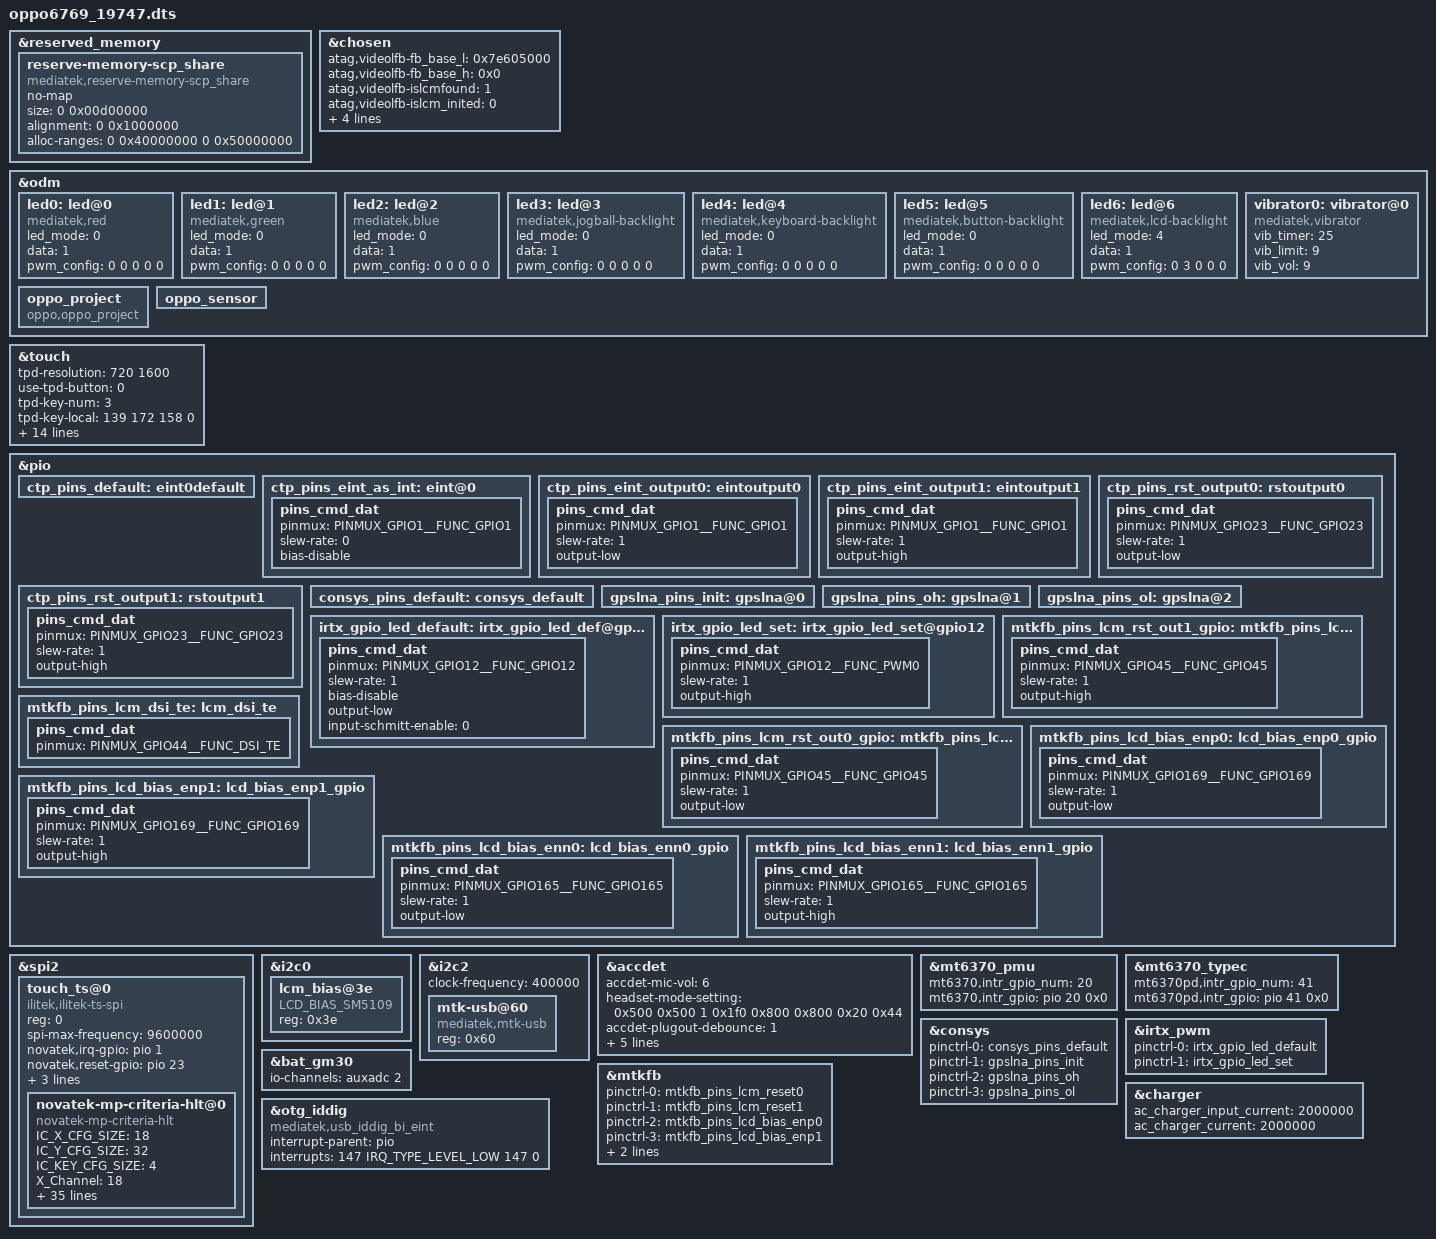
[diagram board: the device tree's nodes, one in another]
/*
 * Copyright (C) 2019 MediaTek Inc.
 *
 * This program is free software; you can redistribute it and/or modify
 * it under the terms of the GNU General Public License version 2 as
 * published by the Free Software Foundation.
 *
 * This program is distributed in the hope that it will be useful,
 * but WITHOUT ANY WARRANTY; without even the implied warranty of
 * MERCHANTABILITY or FITNESS FOR A PARTICULAR PURPOSE.
 * See http://www.gnu.org/licenses/gpl-2.0.html for more details.
 */

/dts-v1/;
/plugin/;
#include <dt-bindings/interrupt-controller/irq.h>
#include <dt-bindings/interrupt-controller/arm-gic.h>
#include <dt-bindings/pinctrl/mt6768-pinfunc.h>

&reserved_memory {
	reserve-memory-scp_share {
		compatible = "mediatek,reserve-memory-scp_share";
		no-map;
		size = <0 0x00d00000>;
		alignment = <0 0x1000000>;
		alloc-ranges = <0 0x40000000 0 0x50000000>;
	};
};

/* chosen */
&chosen {

	atag,videolfb-fb_base_l = <0x7e605000>;
	atag,videolfb-fb_base_h = <0x0>;
	atag,videolfb-islcmfound = <1>;
	atag,videolfb-islcm_inited = <0>;
	atag,videolfb-fps= <6000>;
	atag,videolfb-vramSize= <0x017e8000>;
	atag,videolfb-lcmname=
		"hx83112b_fhdp_dsi_cmd_auo_rt5081_drv";
};

&odm {
	led0:led@0 {
		compatible = "mediatek,red";
		led_mode = <0>;
		data = <1>;
		pwm_config = <0 0 0 0 0>;
	};
	led1:led@1 {
		compatible = "mediatek,green";
		led_mode = <0>;
		data = <1>;
		pwm_config = <0 0 0 0 0>;
	};
	led2:led@2 {
		compatible = "mediatek,blue";
		led_mode = <0>;
		data = <1>;
		pwm_config = <0 0 0 0 0>;
	};
	led3:led@3 {
		compatible = "mediatek,jogball-backlight";
		led_mode = <0>;
		data = <1>;
		pwm_config = <0 0 0 0 0>;
	};
	led4:led@4 {
		compatible = "mediatek,keyboard-backlight";
		led_mode = <0>;
		data = <1>;
		pwm_config = <0 0 0 0 0>;
	};
	led5:led@5 {
		compatible = "mediatek,button-backlight";
		led_mode = <0>;
		data = <1>;
		pwm_config = <0 0 0 0 0>;
	};
	led6:led@6 {
		compatible = "mediatek,lcd-backlight";
		led_mode = <4>;
		data = <1>;
		pwm_config = <0 3 0 0 0>;
	};
	vibrator0:vibrator@0 {
		compatible = "mediatek,vibrator";
		vib_timer = <25>;
		vib_limit = <9>;
		vib_vol= <9>;
	};
	
//#ifdef VENDOR_EDIT
/*Bin.Li@EXP.BSP.bootloader.bootflow, 2017/05/15, Add for oppo project */
	oppo_project:oppo_project {
		compatible = "oppo,oppo_project";
	};
//#endif /*VENDOR_EDIT*/
//#ifdef VENDOR_EDIT
/*Fei.Mo@PSW.BSP.Sensor, 2017/12/18, Add for sensor calibration paramaters */
       oppo_sensor:oppo_sensor {
       };
//#endif /*VENDOR_EDIT*
};

/* TOUCH start */
&touch {
	tpd-resolution = <720 1600>;
	use-tpd-button = <0>;
	tpd-key-num = <3>;
	tpd-key-local= <139 172 158 0>;
	tpd-key-dim-local = <90 883 100 40 230
				883 100 40 370 883 100 40 0 0 0 0>;
	tpd-max-touch-num = <10>;
	tpd-filter-enable = <0>;
	tpd-filter-pixel-density = <168>;
	tpd-filter-custom-prameters = <0 0 0 0 0 0 0 0 0 0 0 0>;
	tpd-filter-custom-speed = <0 0 0>;
	pinctrl-names = "default", "state_eint_as_int",
		"state_eint_output0", "state_eint_output1",
		"state_rst_output0", "state_rst_output1";
	pinctrl-0 = <&ctp_pins_default>;
	pinctrl-1 = <&ctp_pins_eint_as_int>;
	pinctrl-2 = <&ctp_pins_eint_output0>;
	pinctrl-3 = <&ctp_pins_eint_output1>;
	pinctrl-4 = <&ctp_pins_rst_output0>;
	pinctrl-5 = <&ctp_pins_rst_output1>;
	status = "okay";
};
&pio {
	ctp_pins_default: eint0default {
	};
	ctp_pins_eint_as_int: eint@0 {
		pins_cmd_dat {
			pinmux = <PINMUX_GPIO1__FUNC_GPIO1>;
			slew-rate = <0>;
			bias-disable;
		};
	};
	ctp_pins_eint_output0: eintoutput0 {
		pins_cmd_dat {
			pinmux = <PINMUX_GPIO1__FUNC_GPIO1>;
			slew-rate = <1>;
			output-low;
		};
	};
	ctp_pins_eint_output1: eintoutput1 {
		pins_cmd_dat {
			pinmux = <PINMUX_GPIO1__FUNC_GPIO1>;
			slew-rate = <1>;
			output-high;
	};
	};
	ctp_pins_rst_output0: rstoutput0 {
		pins_cmd_dat {
			pinmux = <PINMUX_GPIO23__FUNC_GPIO23>;
			slew-rate = <1>;
			output-low;
		};
	};
	ctp_pins_rst_output1: rstoutput1 {
		pins_cmd_dat {
			pinmux = <PINMUX_GPIO23__FUNC_GPIO23>;
			slew-rate = <1>;
			output-high;
		};
	};
};
//#ifdef ODM_WT_EDIT
//#Tongxing.Liu@ODM_WT.BSP.Touchscreen.Base,2019/10/04,bringup add for xl and hlt touchscreen mould dts config.
&spi2 {
    #address-cells = <1>;
    #size-cells = <0>;
    touch_ts@0 {
        reg = <0>;
        compatible = "ilitek,ilitek-ts-spi","novatek,NVT-ts-spi";
	status = "okay";
	/* touch spi config */
        spi-max-frequency = <9600000>;
	/* novatek touch gpio config */
	novatek,irq-gpio = <&pio 1 0>;
	novatek,reset-gpio = <&pio 23 0>;
	novatek,reset_global_gpio = <&pio 45 0>;
	/* 672A, 525B */
	novatek,swrst-n8-addr = <0x03F0FE>;
	/* MP config  */
	novatek,mp-support-dt;
	novatek-mp-criteria-hlt@0 {
		#address-cells = <1>;
		#size-cells = <0>;
		compatible = "novatek-mp-criteria-hlt";
	        /* MP Config */
		IC_X_CFG_SIZE = <18>;
		IC_Y_CFG_SIZE = <32>;
		IC_KEY_CFG_SIZE = <4>;
		X_Channel = <18>;
		Y_Channel = <32>;
		AIN_X = <0 1 2 3 4 5 6 7 8 9 10 11 12 13 14 15 16 17>;
		AIN_Y = <0 1 2 3 4 5 6 7 8 9 10 11 12 13 14 15 16 17 18 19
							20 21 22 23 24 25 26 27 28 29 30 31>;
		AIN_KEY = <0 1 2 0xFF>;

		/* MP Criteria */
		PS_Config_Lmt_Short_Rawdata_P = <
			14008 14008 14008 14008 14008 14008 14008 14008 14008 14008 14008 14008 14008 14008 14008 14008 14008 14008
			14008 14008 14008 14008 14008 14008 14008 14008 14008 14008 14008 14008 14008 14008 14008 14008 14008 14008
			14008 14008 14008 14008 14008 14008 14008 14008 14008 14008 14008 14008 14008 14008 14008 14008 14008 14008
			14008 14008 14008 14008 14008 14008 14008 14008 14008 14008 14008 14008 14008 14008 14008 14008 14008 14008
			14008 14008 14008 14008 14008 14008 14008 14008 14008 14008 14008 14008 14008 14008 14008 14008 14008 14008
			14008 14008 14008 14008 14008 14008 14008 14008 14008 14008 14008 14008 14008 14008 14008 14008 14008 14008
			14008 14008 14008 14008 14008 14008 14008 14008 14008 14008 14008 14008 14008 14008 14008 14008 14008 14008
			14008 14008 14008 14008 14008 14008 14008 14008 14008 14008 14008 14008 14008 14008 14008 14008 14008 14008
			14008 14008 14008 14008 14008 14008 14008 14008 14008 14008 14008 14008 14008 14008 14008 14008 14008 14008
			14008 14008 14008 14008 14008 14008 14008 14008 14008 14008 14008 14008 14008 14008 14008 14008 14008 14008
			14008 14008 14008 14008 14008 14008 14008 14008 14008 14008 14008 14008 14008 14008 14008 14008 14008 14008
			14008 14008 14008 14008 14008 14008 14008 14008 14008 14008 14008 14008 14008 14008 14008 14008 14008 14008
			14008 14008 14008 14008 14008 14008 14008 14008 14008 14008 14008 14008 14008 14008 14008 14008 14008 14008
			14008 14008 14008 14008 14008 14008 14008 14008 14008 14008 14008 14008 14008 14008 14008 14008 14008 14008
			14008 14008 14008 14008 14008 14008 14008 14008 14008 14008 14008 14008 14008 14008 14008 14008 14008 14008
			14008 14008 14008 14008 14008 14008 14008 14008 14008 14008 14008 14008 14008 14008 14008 14008 14008 14008
			14008 14008 14008 14008 14008 14008 14008 14008 14008 14008 14008 14008 14008 14008 14008 14008 14008 14008
			14008 14008 14008 14008 14008 14008 14008 14008 14008 14008 14008 14008 14008 14008 14008 14008 14008 14008
			14008 14008 14008 14008 14008 14008 14008 14008 14008 14008 14008 14008 14008 14008 14008 14008 14008 14008
			14008 14008 14008 14008 14008 14008 14008 14008 14008 14008 14008 14008 14008 14008 14008 14008 14008 14008
			14008 14008 14008 14008 14008 14008 14008 14008 14008 14008 14008 14008 14008 14008 14008 14008 14008 14008
			14008 14008 14008 14008 14008 14008 14008 14008 14008 14008 14008 14008 14008 14008 14008 14008 14008 14008
			14008 14008 14008 14008 14008 14008 14008 14008 14008 14008 14008 14008 14008 14008 14008 14008 14008 14008
			14008 14008 14008 14008 14008 14008 14008 14008 14008 14008 14008 14008 14008 14008 14008 14008 14008 14008
			14008 14008 14008 14008 14008 14008 14008 14008 14008 14008 14008 14008 14008 14008 14008 14008 14008 14008
			14008 14008 14008 14008 14008 14008 14008 14008 14008 14008 14008 14008 14008 14008 14008 14008 14008 14008
			14008 14008 14008 14008 14008 14008 14008 14008 14008 14008 14008 14008 14008 14008 14008 14008 14008 14008
			14008 14008 14008 14008 14008 14008 14008 14008 14008 14008 14008 14008 14008 14008 14008 14008 14008 14008
			14008 14008 14008 14008 14008 14008 14008 14008 14008 14008 14008 14008 14008 14008 14008 14008 14008 14008
			14008 14008 14008 14008 14008 14008 14008 14008 14008 14008 14008 14008 14008 14008 14008 14008 14008 14008
			14008 14008 14008 14008 14008 14008 14008 14008 14008 14008 14008 14008 14008 14008 14008 14008 14008 14008
			14008 14008 14008 14008 14008 14008 14008 14008 14008 14008 14008 14008 14008 14008 14008 14008 14008 14008
			>;

		PS_Config_Lmt_Short_Rawdata_N = <
			10000 10000 10000 10000 10000 10000 10000 10000 10000 10000 10000 10000 10000 10000 10000 10000 10000 10000
			10000 10000 10000 10000 10000 10000 10000 10000 10000 10000 10000 10000 10000 10000 10000 10000 10000 10000
			10000 10000 10000 10000 10000 10000 10000 10000 10000 10000 10000 10000 10000 10000 10000 10000 10000 10000
			10000 10000 10000 10000 10000 10000 10000 10000 10000 10000 10000 10000 10000 10000 10000 10000 10000 10000
			10000 10000 10000 10000 10000 10000 10000 10000 10000 10000 10000 10000 10000 10000 10000 10000 10000 10000
			10000 10000 10000 10000 10000 10000 10000 10000 10000 10000 10000 10000 10000 10000 10000 10000 10000 10000
			10000 10000 10000 10000 10000 10000 10000 10000 10000 10000 10000 10000 10000 10000 10000 10000 10000 10000
			10000 10000 10000 10000 10000 10000 10000 10000 10000 10000 10000 10000 10000 10000 10000 10000 10000 10000
			10000 10000 10000 10000 10000 10000 10000 10000 10000 10000 10000 10000 10000 10000 10000 10000 10000 10000
			10000 10000 10000 10000 10000 10000 10000 10000 10000 10000 10000 10000 10000 10000 10000 10000 10000 10000
			10000 10000 10000 10000 10000 10000 10000 10000 10000 10000 10000 10000 10000 10000 10000 10000 10000 10000
			10000 10000 10000 10000 10000 10000 10000 10000 10000 10000 10000 10000 10000 10000 10000 10000 10000 10000
			10000 10000 10000 10000 10000 10000 10000 10000 10000 10000 10000 10000 10000 10000 10000 10000 10000 10000
			10000 10000 10000 10000 10000 10000 10000 10000 10000 10000 10000 10000 10000 10000 10000 10000 10000 10000
			10000 10000 10000 10000 10000 10000 10000 10000 10000 10000 10000 10000 10000 10000 10000 10000 10000 10000
			10000 10000 10000 10000 10000 10000 10000 10000 10000 10000 10000 10000 10000 10000 10000 10000 10000 10000
			10000 10000 10000 10000 10000 10000 10000 10000 10000 10000 10000 10000 10000 10000 10000 10000 10000 10000
			10000 10000 10000 10000 10000 10000 10000 10000 10000 10000 10000 10000 10000 10000 10000 10000 10000 10000
			10000 10000 10000 10000 10000 10000 10000 10000 10000 10000 10000 10000 10000 10000 10000 10000 10000 10000
			10000 10000 10000 10000 10000 10000 10000 10000 10000 10000 10000 10000 10000 10000 10000 10000 10000 10000
			10000 10000 10000 10000 10000 10000 10000 10000 10000 10000 10000 10000 10000 10000 10000 10000 10000 10000
			10000 10000 10000 10000 10000 10000 10000 10000 10000 10000 10000 10000 10000 10000 10000 10000 10000 10000
			10000 10000 10000 10000 10000 10000 10000 10000 10000 10000 10000 10000 10000 10000 10000 10000 10000 10000
			10000 10000 10000 10000 10000 10000 10000 10000 10000 10000 10000 10000 10000 10000 10000 10000 10000 10000
			10000 10000 10000 10000 10000 10000 10000 10000 10000 10000 10000 10000 10000 10000 10000 10000 10000 10000
			10000 10000 10000 10000 10000 10000 10000 10000 10000 10000 10000 10000 10000 10000 10000 10000 10000 10000
			10000 10000 10000 10000 10000 10000 10000 10000 10000 10000 10000 10000 10000 10000 10000 10000 10000 10000
			10000 10000 10000 10000 10000 10000 10000 10000 10000 10000 10000 10000 10000 10000 10000 10000 10000 10000
			10000 10000 10000 10000 10000 10000 10000 10000 10000 10000 10000 10000 10000 10000 10000 10000 10000 10000
			10000 10000 10000 10000 10000 10000 10000 10000 10000 10000 10000 10000 10000 10000 10000 10000 10000 10000
			10000 10000 10000 10000 10000 10000 10000 10000 10000 10000 10000 10000 10000 10000 10000 10000 10000 10000
			10000 10000 10000 10000 10000 10000 10000 10000 10000 10000 10000 10000 10000 10000 10000 10000 10000 10000
			>;

		PS_Config_Lmt_Open_Rawdata_P = <
			4096 4096 4096 4096 4096 4096 4096 4096 4096 4096 4096 4096 4096 4096 4096 4096 4096 4096
			4096 4096 4096 4096 4096 4096 4096 4096 4096 4096 4096 4096 4096 4096 4096 4096 4096 4096
			4096 4096 4096 4096 4096 4096 4096 4096 4096 4096 4096 4096 4096 4096 4096 4096 4096 4096
			4096 4096 4096 4096 4096 4096 4096 4096 4096 4096 4096 4096 4096 4096 4096 4096 4096 4096
			4096 4096 4096 4096 4096 4096 4096 4096 4096 4096 4096 4096 4096 4096 4096 4096 4096 4096
			4096 4096 4096 4096 4096 4096 4096 4096 4096 4096 4096 4096 4096 4096 4096 4096 4096 4096
			4096 4096 4096 4096 4096 4096 4096 4096 4096 4096 4096 4096 4096 4096 4096 4096 4096 4096
			4096 4096 4096 4096 4096 4096 4096 4096 4096 4096 4096 4096 4096 4096 4096 4096 4096 4096
			4096 4096 4096 4096 4096 4096 4096 4096 4096 4096 4096 4096 4096 4096 4096 4096 4096 4096
			4096 4096 4096 4096 4096 4096 4096 4096 4096 4096 4096 4096 4096 4096 4096 4096 4096 4096
			4096 4096 4096 4096 4096 4096 4096 4096 4096 4096 4096 4096 4096 4096 4096 4096 4096 4096
			4096 4096 4096 4096 4096 4096 4096 4096 4096 4096 4096 4096 4096 4096 4096 4096 4096 4096
			4096 4096 4096 4096 4096 4096 4096 4096 4096 4096 4096 4096 4096 4096 4096 4096 4096 4096
			4096 4096 4096 4096 4096 4096 4096 4096 4096 4096 4096 4096 4096 4096 4096 4096 4096 4096
			4096 4096 4096 4096 4096 4096 4096 4096 4096 4096 4096 4096 4096 4096 4096 4096 4096 4096
			4096 4096 4096 4096 4096 4096 4096 4096 4096 4096 4096 4096 4096 4096 4096 4096 4096 4096
			4096 4096 4096 4096 4096 4096 4096 4096 4096 4096 4096 4096 4096 4096 4096 4096 4096 4096
			4096 4096 4096 4096 4096 4096 4096 4096 4096 4096 4096 4096 4096 4096 4096 4096 4096 4096
			4096 4096 4096 4096 4096 4096 4096 4096 4096 4096 4096 4096 4096 4096 4096 4096 4096 4096
			4096 4096 4096 4096 4096 4096 4096 4096 4096 4096 4096 4096 4096 4096 4096 4096 4096 4096
			4096 4096 4096 4096 4096 4096 4096 4096 4096 4096 4096 4096 4096 4096 4096 4096 4096 4096
			4096 4096 4096 4096 4096 4096 4096 4096 4096 4096 4096 4096 4096 4096 4096 4096 4096 4096
			4096 4096 4096 4096 4096 4096 4096 4096 4096 4096 4096 4096 4096 4096 4096 4096 4096 4096
			4096 4096 4096 4096 4096 4096 4096 4096 4096 4096 4096 4096 4096 4096 4096 4096 4096 4096
			4096 4096 4096 4096 4096 4096 4096 4096 4096 4096 4096 4096 4096 4096 4096 4096 4096 4096
			4096 4096 4096 4096 4096 4096 4096 4096 4096 4096 4096 4096 4096 4096 4096 4096 4096 4096
			4096 4096 4096 4096 4096 4096 4096 4096 4096 4096 4096 4096 4096 4096 4096 4096 4096 4096
			4096 4096 4096 4096 4096 4096 4096 4096 4096 4096 4096 4096 4096 4096 4096 4096 4096 4096
			4096 4096 4096 4096 4096 4096 4096 4096 4096 4096 4096 4096 4096 4096 4096 4096 4096 4096
			4096 4096 4096 4096 4096 4096 4096 4096 4096 4096 4096 4096 4096 4096 4096 4096 4096 4096
			4096 4096 4096 4096 4096 4096 4096 4096 4096 4096 4096 4096 4096 4096 4096 4096 4096 4096
			4096 4096 4096 4096 4096 4096 4096 4096 4096 4096 4096 4096 4096 4096 4096 4096 4096 4096
			>;

		PS_Config_Lmt_Open_Rawdata_N = <
			50 50 50 50 50 50 50 50 50 50 50 50 50 50 50 50 50 50
			50 50 50 50 50 50 50 50 50 50 50 50 50 50 50 50 50 50
			50 50 50 50 50 50 50 50 50 50 50 50 50 50 50 50 50 50
			50 50 50 50 50 50 50 50 50 50 50 50 50 50 50 50 50 50
			50 50 50 50 50 50 50 50 50 50 50 50 50 50 50 50 50 50
			50 50 50 50 50 50 50 50 50 50 50 50 50 50 50 50 50 50
			50 50 50 50 50 50 50 50 50 50 50 50 50 50 50 50 50 50
			50 50 50 50 50 50 50 50 50 50 50 50 50 50 50 50 50 50
			50 50 50 50 50 50 50 50 50 50 50 50 50 50 50 50 50 50
			50 50 50 50 50 50 50 50 50 50 50 50 50 50 50 50 50 50
			50 50 50 50 50 50 50 50 50 50 50 50 50 50 50 50 50 50
			50 50 50 50 50 50 50 50 50 50 50 50 50 50 50 50 50 50
			50 50 50 50 50 50 50 50 50 50 50 50 50 50 50 50 50 50
			50 50 50 50 50 50 50 50 50 50 50 50 50 50 50 50 50 50
			50 50 50 50 50 50 50 50 50 50 50 50 50 50 50 50 50 50
			50 50 50 50 50 50 50 50 50 50 50 50 50 50 50 50 50 50
			50 50 50 50 50 50 50 50 50 50 50 50 50 50 50 50 50 50
			50 50 50 50 50 50 50 50 50 50 50 50 50 50 50 50 50 50
			50 50 50 50 50 50 50 50 50 50 50 50 50 50 50 50 50 50
			50 50 50 50 50 50 50 50 50 50 50 50 50 50 50 50 50 50
			50 50 50 50 50 50 50 50 50 50 50 50 50 50 50 50 50 50
			50 50 50 50 50 50 50 50 50 50 50 50 50 50 50 50 50 50
			50 50 50 50 50 50 50 50 50 50 50 50 50 50 50 50 50 50
			50 50 50 50 50 50 50 50 50 50 50 50 50 50 50 50 50 50
			50 50 50 50 50 50 50 50 50 50 50 50 50 50 50 50 50 50
			50 50 50 50 50 50 50 50 50 50 50 50 50 50 50 50 50 50
			50 50 50 50 50 50 50 50 50 50 50 50 50 50 50 50 50 50
			50 50 50 50 50 50 50 50 50 50 50 50 50 50 50 50 50 50
			50 50 50 50 50 50 50 50 50 50 50 50 50 50 50 50 50 50
			50 50 50 50 50 50 50 50 50 50 50 50 50 50 50 50 50 50
			50 50 50 50 50 50 50 50 50 50 50 50 50 50 50 50 50 50
			50 50 50 50 50 50 50 50 50 50 50 50 50 50 50 50 50 50
			>;

		PS_Config_Lmt_FW_Rawdata_P = <
			1920 1920 1920 1920 1920 1920 1920 1920 1920 1920 1920 1920 1920 1920 1920 1920 1920 1920
			1920 1920 1920 1920 1920 1920 1920 1920 1920 1920 1920 1920 1920 1920 1920 1920 1920 1920
			1920 1920 1920 1920 1920 1920 1920 1920 1920 1920 1920 1920 1920 1920 1920 1920 1920 1920
			1920 1920 1920 1920 1920 1920 1920 1920 1920 1920 1920 1920 1920 1920 1920 1920 1920 1920
			1920 1920 1920 1920 1920 1920 1920 1920 1920 1920 1920 1920 1920 1920 1920 1920 1920 1920
			1920 1920 1920 1920 1920 1920 1920 1920 1920 1920 1920 1920 1920 1920 1920 1920 1920 1920
			1920 1920 1920 1920 1920 1920 1920 1920 1920 1920 1920 1920 1920 1920 1920 1920 1920 1920
			1920 1920 1920 1920 1920 1920 1920 1920 1920 1920 1920 1920 1920 1920 1920 1920 1920 1920
			1920 1920 1920 1920 1920 1920 1920 1920 1920 1920 1920 1920 1920 1920 1920 1920 1920 1920
			1920 1920 1920 1920 1920 1920 1920 1920 1920 1920 1920 1920 1920 1920 1920 1920 1920 1920
			1920 1920 1920 1920 1920 1920 1920 1920 1920 1920 1920 1920 1920 1920 1920 1920 1920 1920
			1920 1920 1920 1920 1920 1920 1920 1920 1920 1920 1920 1920 1920 1920 1920 1920 1920 1920
			1920 1920 1920 1920 1920 1920 1920 1920 1920 1920 1920 1920 1920 1920 1920 1920 1920 1920
			1920 1920 1920 1920 1920 1920 1920 1920 1920 1920 1920 1920 1920 1920 1920 1920 1920 1920
			1920 1920 1920 1920 1920 1920 1920 1920 1920 1920 1920 1920 1920 1920 1920 1920 1920 1920
			1920 1920 1920 1920 1920 1920 1920 1920 1920 1920 1920 1920 1920 1920 1920 1920 1920 1920
			1920 1920 1920 1920 1920 1920 1920 1920 1920 1920 1920 1920 1920 1920 1920 1920 1920 1920
			1920 1920 1920 1920 1920 1920 1920 1920 1920 1920 1920 1920 1920 1920 1920 1920 1920 1920
			1920 1920 1920 1920 1920 1920 1920 1920 1920 1920 1920 1920 1920 1920 1920 1920 1920 1920
			1920 1920 1920 1920 1920 1920 1920 1920 1920 1920 1920 1920 1920 1920 1920 1920 1920 1920
			1920 1920 1920 1920 1920 1920 1920 1920 1920 1920 1920 1920 1920 1920 1920 1920 1920 1920
			1920 1920 1920 1920 1920 1920 1920 1920 1920 1920 1920 1920 1920 1920 1920 1920 1920 1920
			1920 1920 1920 1920 1920 1920 1920 1920 1920 1920 1920 1920 1920 1920 1920 1920 1920 1920
			1920 1920 1920 1920 1920 1920 1920 1920 1920 1920 1920 1920 1920 1920 1920 1920 1920 1920
			1920 1920 1920 1920 1920 1920 1920 1920 1920 1920 1920 1920 1920 1920 1920 1920 1920 1920
			1920 1920 1920 1920 1920 1920 1920 1920 1920 1920 1920 1920 1920 1920 1920 1920 1920 1920
			1920 1920 1920 1920 1920 1920 1920 1920 1920 1920 1920 1920 1920 1920 1920 1920 1920 1920
			1920 1920 1920 1920 1920 1920 1920 1920 1920 1920 1920 1920 1920 1920 1920 1920 1920 1920
			1920 1920 1920 1920 1920 1920 1920 1920 1920 1920 1920 1920 1920 1920 1920 1920 1920 1920
			1920 1920 1920 1920 1920 1920 1920 1920 1920 1920 1920 1920 1920 1920 1920 1920 1920 1920
			1920 1920 1920 1920 1920 1920 1920 1920 1920 1920 1920 1920 1920 1920 1920 1920 1920 1920
			1920 1920 1920 1920 1920 1920 1920 1920 1920 1920 1920 1920 1920 1920 1920 1920 1920 1920
			>;

		PS_Config_Lmt_FW_Rawdata_N = <
			240 240 240 240 240 240 240 240 240 240 240 240 240 240 240 240 240 240
			240 240 240 240 240 240 240 240 240 240 240 240 240 240 240 240 240 240
			240 240 240 240 240 240 240 240 240 240 240 240 240 240 240 240 240 240
			240 240 240 240 240 240 240 240 240 240 240 240 240 240 240 240 240 240
			240 240 240 240 240 240 240 240 240 240 240 240 240 240 240 240 240 240
			240 240 240 240 240 240 240 240 240 240 240 240 240 240 240 240 240 240
			240 240 240 240 240 240 240 240 240 240 240 240 240 240 240 240 240 240
			240 240 240 240 240 240 240 240 240 240 240 240 240 240 240 240 240 240
			240 240 240 240 240 240 240 240 240 240 240 240 240 240 240 240 240 240
			240 240 240 240 240 240 240 240 240 240 240 240 240 240 240 240 240 240
			240 240 240 240 240 240 240 240 240 240 240 240 240 240 240 240 240 240
			240 240 240 240 240 240 240 240 240 240 240 240 240 240 240 240 240 240
			240 240 240 240 240 240 240 240 240 240 240 240 240 240 240 240 240 240
			240 240 240 240 240 240 240 240 240 240 240 240 240 240 240 240 240 240
			240 240 240 240 240 240 240 240 240 240 240 240 240 240 240 240 240 240
			240 240 240 240 240 240 240 240 240 240 240 240 240 240 240 240 240 240
			240 240 240 240 240 240 240 240 240 240 240 240 240 240 240 240 240 240
			240 240 240 240 240 240 240 240 240 240 240 240 240 240 240 240 240 240
			240 240 240 240 240 240 240 240 240 240 240 240 240 240 240 240 240 240
			240 240 240 240 240 240 240 240 240 240 240 240 240 240 240 240 240 240
			240 240 240 240 240 240 240 240 240 240 240 240 240 240 240 240 240 240
			240 240 240 240 240 240 240 240 240 240 240 240 240 240 240 240 240 240
			240 240 240 240 240 240 240 240 240 240 240 240 240 240 240 240 240 240
			240 240 240 240 240 240 240 240 240 240 240 240 240 240 240 240 240 240
			240 240 240 240 240 240 240 240 240 240 240 240 240 240 240 240 240 240
			240 240 240 240 240 240 240 240 240 240 240 240 240 240 240 240 240 240
			240 240 240 240 240 240 240 240 240 240 240 240 240 240 240 240 240 240
			240 240 240 240 240 240 240 240 240 240 240 240 240 240 240 240 240 240
			240 240 240 240 240 240 240 240 240 240 240 240 240 240 240 240 240 240
			240 240 240 240 240 240 240 240 240 240 240 240 240 240 240 240 240 240
			240 240 240 240 240 240 240 240 240 240 240 240 240 240 240 240 240 240
			240 240 240 240 240 240 240 240 240 240 240 240 240 240 240 240 240 240
			>;

		PS_Config_Lmt_FW_CC_P = <
			314 314 314 314 314 314 314 314 314 314 314 314 314 314 314 314 314 314
			314 314 314 314 314 314 314 314 314 314 314 314 314 314 314 314 314 314
			314 314 314 314 314 314 314 314 314 314 314 314 314 314 314 314 314 314
			314 314 314 314 314 314 314 314 314 314 314 314 314 314 314 314 314 314
			314 314 314 314 314 314 314 314 314 314 314 314 314 314 314 314 314 314
			314 314 314 314 314 314 314 314 314 314 314 314 314 314 314 314 314 314
			314 314 314 314 314 314 314 314 314 314 314 314 314 314 314 314 314 314
			314 314 314 314 314 314 314 314 314 314 314 314 314 314 314 314 314 314
			314 314 314 314 314 314 314 314 314 314 314 314 314 314 314 314 314 314
			314 314 314 314 314 314 314 314 314 314 314 314 314 314 314 314 314 314
			314 314 314 314 314 314 314 314 314 314 314 314 314 314 314 314 314 314
			314 314 314 314 314 314 314 314 314 314 314 314 314 314 314 314 314 314
			314 314 314 314 314 314 314 314 314 314 314 314 314 314 314 314 314 314
			314 314 314 314 314 314 314 314 314 314 314 314 314 314 314 314 314 314
			314 314 314 314 314 314 314 314 314 314 314 314 314 314 314 314 314 314
			314 314 314 314 314 314 314 314 314 314 314 314 314 314 314 314 314 314
			314 314 314 314 314 314 314 314 314 314 314 314 314 314 314 314 314 314
			314 314 314 314 314 314 314 314 314 314 314 314 314 314 314 314 314 314
			314 314 314 314 314 314 314 314 314 314 314 314 314 314 314 314 314 314
			314 314 314 314 314 314 314 314 314 314 314 314 314 314 314 314 314 314
			314 314 314 314 314 314 314 314 314 314 314 314 314 314 314 314 314 314
			314 314 314 314 314 314 314 314 314 314 314 314 314 314 314 314 314 314
			314 314 314 314 314 314 314 314 314 314 314 314 314 314 314 314 314 314
			314 314 314 314 314 314 314 314 314 314 314 314 314 314 314 314 314 314
			314 314 314 314 314 314 314 314 314 314 314 314 314 314 314 314 314 314
			314 314 314 314 314 314 314 314 314 314 314 314 314 314 314 314 314 314
			314 314 314 314 314 314 314 314 314 314 314 314 314 314 314 314 314 314
			314 314 314 314 314 314 314 314 314 314 314 314 314 314 314 314 314 314
			314 314 314 314 314 314 314 314 314 314 314 314 314 314 314 314 314 314
			314 314 314 314 314 314 314 314 314 314 314 314 314 314 314 314 314 314
			314 314 314 314 314 314 314 314 314 314 314 314 314 314 314 314 314 314
			314 314 314 314 314 314 314 314 314 314 314 314 314 314 314 314 314 314
			>;

		PS_Config_Lmt_FW_CC_N = <
			30 30 30 30 30 30 30 30 30 30 30 30 30 30 30 30 30 30
			30 30 30 30 30 30 30 30 30 30 30 30 30 30 30 30 30 30
			30 30 30 30 30 30 30 30 30 30 30 30 30 30 30 30 30 30
			30 30 30 30 30 30 30 30 30 30 30 30 30 30 30 30 30 30
			30 30 30 30 30 30 30 30 30 30 30 30 30 30 30 30 30 30
			30 30 30 30 30 30 30 30 30 30 30 30 30 30 30 30 30 30
			30 30 30 30 30 30 30 30 30 30 30 30 30 30 30 30 30 30
			30 30 30 30 30 30 30 30 30 30 30 30 30 30 30 30 30 30
			30 30 30 30 30 30 30 30 30 30 30 30 30 30 30 30 30 30
			30 30 30 30 30 30 30 30 30 30 30 30 30 30 30 30 30 30
			30 30 30 30 30 30 30 30 30 30 30 30 30 30 30 30 30 30
			30 30 30 30 30 30 30 30 30 30 30 30 30 30 30 30 30 30
			30 30 30 30 30 30 30 30 30 30 30 30 30 30 30 30 30 30
			30 30 30 30 30 30 30 30 30 30 30 30 30 30 30 30 30 30
			30 30 30 30 30 30 30 30 30 30 30 30 30 30 30 30 30 30
			30 30 30 30 30 30 30 30 30 30 30 30 30 30 30 30 30 30
			30 30 30 30 30 30 30 30 30 30 30 30 30 30 30 30 30 30
			30 30 30 30 30 30 30 30 30 30 30 30 30 30 30 30 30 30
			30 30 30 30 30 30 30 30 30 30 30 30 30 30 30 30 30 30
			30 30 30 30 30 30 30 30 30 30 30 30 30 30 30 30 30 30
			30 30 30 30 30 30 30 30 30 30 30 30 30 30 30 30 30 30
			30 30 30 30 30 30 30 30 30 30 30 30 30 30 30 30 30 30
			30 30 30 30 30 30 30 30 30 30 30 30 30 30 30 30 30 30
			30 30 30 30 30 30 30 30 30 30 30 30 30 30 30 30 30 30
			30 30 30 30 30 30 30 30 30 30 30 30 30 30 30 30 30 30
			30 30 30 30 30 30 30 30 30 30 30 30 30 30 30 30 30 30
			30 30 30 30 30 30 30 30 30 30 30 30 30 30 30 30 30 30
			30 30 30 30 30 30 30 30 30 30 30 30 30 30 30 30 30 30
			30 30 30 30 30 30 30 30 30 30 30 30 30 30 30 30 30 30
			30 30 30 30 30 30 30 30 30 30 30 30 30 30 30 30 30 30
			30 30 30 30 30 30 30 30 30 30 30 30 30 30 30 30 30 30
			30 30 30 30 30 30 30 30 30 30 30 30 30 30 30 30 30 30
			>;

		PS_Config_Lmt_FW_Diff_P = <
			75 75 75 75 75 75 75 75 75 75 75 75 75 75 75 75 75 75
			75 75 75 75 75 75 75 75 75 75 75 75 75 75 75 75 75 75
			75 75 75 75 75 75 75 75 75 75 75 75 75 75 75 75 75 75
			75 75 75 75 75 75 75 75 75 75 75 75 75 75 75 75 75 75
			75 75 75 75 75 75 75 75 75 75 75 75 75 75 75 75 75 75
			75 75 75 75 75 75 75 75 75 75 75 75 75 75 75 75 75 75
			75 75 75 75 75 75 75 75 75 75 75 75 75 75 75 75 75 75
			75 75 75 75 75 75 75 75 75 75 75 75 75 75 75 75 75 75
			75 75 75 75 75 75 75 75 75 75 75 75 75 75 75 75 75 75
			75 75 75 75 75 75 75 75 75 75 75 75 75 75 75 75 75 75
			75 75 75 75 75 75 75 75 75 75 75 75 75 75 75 75 75 75
			75 75 75 75 75 75 75 75 75 75 75 75 75 75 75 75 75 75
			75 75 75 75 75 75 75 75 75 75 75 75 75 75 75 75 75 75
			75 75 75 75 75 75 75 75 75 75 75 75 75 75 75 75 75 75
			75 75 75 75 75 75 75 75 75 75 75 75 75 75 75 75 75 75
			75 75 75 75 75 75 75 75 75 75 75 75 75 75 75 75 75 75
			75 75 75 75 75 75 75 75 75 75 75 75 75 75 75 75 75 75
			75 75 75 75 75 75 75 75 75 75 75 75 75 75 75 75 75 75
			75 75 75 75 75 75 75 75 75 75 75 75 75 75 75 75 75 75
			75 75 75 75 75 75 75 75 75 75 75 75 75 75 75 75 75 75
			75 75 75 75 75 75 75 75 75 75 75 75 75 75 75 75 75 75
			75 75 75 75 75 75 75 75 75 75 75 75 75 75 75 75 75 75
			75 75 75 75 75 75 75 75 75 75 75 75 75 75 75 75 75 75
			75 75 75 75 75 75 75 75 75 75 75 75 75 75 75 75 75 75
			75 75 75 75 75 75 75 75 75 75 75 75 75 75 75 75 75 75
			75 75 75 75 75 75 75 75 75 75 75 75 75 75 75 75 75 75
			75 75 75 75 75 75 75 75 75 75 75 75 75 75 75 75 75 75
			75 75 75 75 75 75 75 75 75 75 75 75 75 75 75 75 75 75
			75 75 75 75 75 75 75 75 75 75 75 75 75 75 75 75 75 75
			75 75 75 75 75 75 75 75 75 75 75 75 75 75 75 75 75 75
			75 75 75 75 75 75 75 75 75 75 75 75 75 75 75 75 75 75
			75 75 75 75 75 75 75 75 75 75 75 75 75 75 75 75 75 75
			>;

		PS_Config_Lmt_FW_Diff_N = <
			(-75) (-75) (-75) (-75) (-75) (-75) (-75) (-75) (-75) (-75) (-75) (-75) (-75) (-75) (-75) (-75) (-75) (-75)
			(-75) (-75) (-75) (-75) (-75) (-75) (-75) (-75) (-75) (-75) (-75) (-75) (-75) (-75) (-75) (-75) (-75) (-75)
			(-75) (-75) (-75) (-75) (-75) (-75) (-75) (-75) (-75) (-75) (-75) (-75) (-75) (-75) (-75) (-75) (-75) (-75)
			(-75) (-75) (-75) (-75) (-75) (-75) (-75) (-75) (-75) (-75) (-75) (-75) (-75) (-75) (-75) (-75) (-75) (-75)
			(-75) (-75) (-75) (-75) (-75) (-75) (-75) (-75) (-75) (-75) (-75) (-75) (-75) (-75) (-75) (-75) (-75) (-75)
			(-75) (-75) (-75) (-75) (-75) (-75) (-75) (-75) (-75) (-75) (-75) (-75) (-75) (-75) (-75) (-75) (-75) (-75)
			(-75) (-75) (-75) (-75) (-75) (-75) (-75) (-75) (-75) (-75) (-75) (-75) (-75) (-75) (-75) (-75) (-75) (-75)
			(-75) (-75) (-75) (-75) (-75) (-75) (-75) (-75) (-75) (-75) (-75) (-75) (-75) (-75) (-75) (-75) (-75) (-75)
			(-75) (-75) (-75) (-75) (-75) (-75) (-75) (-75) (-75) (-75) (-75) (-75) (-75) (-75) (-75) (-75) (-75) (-75)
			(-75) (-75) (-75) (-75) (-75) (-75) (-75) (-75) (-75) (-75) (-75) (-75) (-75) (-75) (-75) (-75) (-75) (-75)
			(-75) (-75) (-75) (-75) (-75) (-75) (-75) (-75) (-75) (-75) (-75) (-75) (-75) (-75) (-75) (-75) (-75) (-75)
			(-75) (-75) (-75) (-75) (-75) (-75) (-75) (-75) (-75) (-75) (-75) (-75) (-75) (-75) (-75) (-75) (-75) (-75)
			(-75) (-75) (-75) (-75) (-75) (-75) (-75) (-75) (-75) (-75) (-75) (-75) (-75) (-75) (-75) (-75) (-75) (-75)
			(-75) (-75) (-75) (-75) (-75) (-75) (-75) (-75) (-75) (-75) (-75) (-75) (-75) (-75) (-75) (-75) (-75) (-75)
			(-75) (-75) (-75) (-75) (-75) (-75) (-75) (-75) (-75) (-75) (-75) (-75) (-75) (-75) (-75) (-75) (-75) (-75)
			(-75) (-75) (-75) (-75) (-75) (-75) (-75) (-75) (-75) (-75) (-75) (-75) (-75) (-75) (-75) (-75) (-75) (-75)
			(-75) (-75) (-75) (-75) (-75) (-75) (-75) (-75) (-75) (-75) (-75) (-75) (-75) (-75) (-75) (-75) (-75) (-75)
			(-75) (-75) (-75) (-75) (-75) (-75) (-75) (-75) (-75) (-75) (-75) (-75) (-75) (-75) (-75) (-75) (-75) (-75)
			(-75) (-75) (-75) (-75) (-75) (-75) (-75) (-75) (-75) (-75) (-75) (-75) (-75) (-75) (-75) (-75) (-75) (-75)
			(-75) (-75) (-75) (-75) (-75) (-75) (-75) (-75) (-75) (-75) (-75) (-75) (-75) (-75) (-75) (-75) (-75) (-75)
			(-75) (-75) (-75) (-75) (-75) (-75) (-75) (-75) (-75) (-75) (-75) (-75) (-75) (-75) (-75) (-75) (-75) (-75)
			(-75) (-75) (-75) (-75) (-75) (-75) (-75) (-75) (-75) (-75) (-75) (-75) (-75) (-75) (-75) (-75) (-75) (-75)
			(-75) (-75) (-75) (-75) (-75) (-75) (-75) (-75) (-75) (-75) (-75) (-75) (-75) (-75) (-75) (-75) (-75) (-75)
			(-75) (-75) (-75) (-75) (-75) (-75) (-75) (-75) (-75) (-75) (-75) (-75) (-75) (-75) (-75) (-75) (-75) (-75)
			(-75) (-75) (-75) (-75) (-75) (-75) (-75) (-75) (-75) (-75) (-75) (-75) (-75) (-75) (-75) (-75) (-75) (-75)
			(-75) (-75) (-75) (-75) (-75) (-75) (-75) (-75) (-75) (-75) (-75) (-75) (-75) (-75) (-75) (-75) (-75) (-75)
			(-75) (-75) (-75) (-75) (-75) (-75) (-75) (-75) (-75) (-75) (-75) (-75) (-75) (-75) (-75) (-75) (-75) (-75)
			(-75) (-75) (-75) (-75) (-75) (-75) (-75) (-75) (-75) (-75) (-75) (-75) (-75) (-75) (-75) (-75) (-75) (-75)
			(-75) (-75) (-75) (-75) (-75) (-75) (-75) (-75) (-75) (-75) (-75) (-75) (-75) (-75) (-75) (-75) (-75) (-75)
			(-75) (-75) (-75) (-75) (-75) (-75) (-75) (-75) (-75) (-75) (-75) (-75) (-75) (-75) (-75) (-75) (-75) (-75)
			(-75) (-75) (-75) (-75) (-75) (-75) (-75) (-75) (-75) (-75) (-75) (-75) (-75) (-75) (-75) (-75) (-75) (-75)
			(-75) (-75) (-75) (-75) (-75) (-75) (-75) (-75) (-75) (-75) (-75) (-75) (-75) (-75) (-75) (-75) (-75) (-75)
			>;

		PS_Config_Diff_Test_Frame = <50>;

		PS_Config_Lmt_LPWG_Rawdata_P = <
			1920 1920 1920 1920 1920 1920 1920 1920 1920 1920 1920 1920 1920 1920 1920 1920 1920 1920
			1920 1920 1920 1920 1920 1920 1920 1920 1920 1920 1920 1920 1920 1920 1920 1920 1920 1920
			1920 1920 1920 1920 1920 1920 1920 1920 1920 1920 1920 1920 1920 1920 1920 1920 1920 1920
			1920 1920 1920 1920 1920 1920 1920 1920 1920 1920 1920 1920 1920 1920 1920 1920 1920 1920
			1920 1920 1920 1920 1920 1920 1920 1920 1920 1920 1920 1920 1920 1920 1920 1920 1920 1920
			1920 1920 1920 1920 1920 1920 1920 1920 1920 1920 1920 1920 1920 1920 1920 1920 1920 1920
			1920 1920 1920 1920 1920 1920 1920 1920 1920 1920 1920 1920 1920 1920 1920 1920 1920 1920
			1920 1920 1920 1920 1920 1920 1920 1920 1920 1920 1920 1920 1920 1920 1920 1920 1920 1920
			1920 1920 1920 1920 1920 1920 1920 1920 1920 1920 1920 1920 1920 1920 1920 1920 1920 1920
			1920 1920 1920 1920 1920 1920 1920 1920 1920 1920 1920 1920 1920 1920 1920 1920 1920 1920
			1920 1920 1920 1920 1920 1920 1920 1920 1920 1920 1920 1920 1920 1920 1920 1920 1920 1920
			1920 1920 1920 1920 1920 1920 1920 1920 1920 1920 1920 1920 1920 1920 1920 1920 1920 1920
			1920 1920 1920 1920 1920 1920 1920 1920 1920 1920 1920 1920 1920 1920 1920 1920 1920 1920
			1920 1920 1920 1920 1920 1920 1920 1920 1920 1920 1920 1920 1920 1920 1920 1920 1920 1920
			1920 1920 1920 1920 1920 1920 1920 1920 1920 1920 1920 1920 1920 1920 1920 1920 1920 1920
			1920 1920 1920 1920 1920 1920 1920 1920 1920 1920 1920 1920 1920 1920 1920 1920 1920 1920
			1920 1920 1920 1920 1920 1920 1920 1920 1920 1920 1920 1920 1920 1920 1920 1920 1920 1920
			1920 1920 1920 1920 1920 1920 1920 1920 1920 1920 1920 1920 1920 1920 1920 1920 1920 1920
			1920 1920 1920 1920 1920 1920 1920 1920 1920 1920 1920 1920 1920 1920 1920 1920 1920 1920
			1920 1920 1920 1920 1920 1920 1920 1920 1920 1920 1920 1920 1920 1920 1920 1920 1920 1920
			1920 1920 1920 1920 1920 1920 1920 1920 1920 1920 1920 1920 1920 1920 1920 1920 1920 1920
			1920 1920 1920 1920 1920 1920 1920 1920 1920 1920 1920 1920 1920 1920 1920 1920 1920 1920
			1920 1920 1920 1920 1920 1920 1920 1920 1920 1920 1920 1920 1920 1920 1920 1920 1920 1920
			1920 1920 1920 1920 1920 1920 1920 1920 1920 1920 1920 1920 1920 1920 1920 1920 1920 1920
			1920 1920 1920 1920 1920 1920 1920 1920 1920 1920 1920 1920 1920 1920 1920 1920 1920 1920
			1920 1920 1920 1920 1920 1920 1920 1920 1920 1920 1920 1920 1920 1920 1920 1920 1920 1920
			1920 1920 1920 1920 1920 1920 1920 1920 1920 1920 1920 1920 1920 1920 1920 1920 1920 1920
			1920 1920 1920 1920 1920 1920 1920 1920 1920 1920 1920 1920 1920 1920 1920 1920 1920 1920
			1920 1920 1920 1920 1920 1920 1920 1920 1920 1920 1920 1920 1920 1920 1920 1920 1920 1920
			1920 1920 1920 1920 1920 1920 1920 1920 1920 1920 1920 1920 1920 1920 1920 1920 1920 1920
			1920 1920 1920 1920 1920 1920 1920 1920 1920 1920 1920 1920 1920 1920 1920 1920 1920 1920
			1920 1920 1920 1920 1920 1920 1920 1920 1920 1920 1920 1920 1920 1920 1920 1920 1920 1920
			>;

		PS_Config_Lmt_LPWG_Rawdata_N = <
			240 240 240 240 240 240 240 240 240 240 240 240 240 240 240 240 240 240
			240 240 240 240 240 240 240 240 240 240 240 240 240 240 240 240 240 240
			240 240 240 240 240 240 240 240 240 240 240 240 240 240 240 240 240 240
			240 240 240 240 240 240 240 240 240 240 240 240 240 240 240 240 240 240
			240 240 240 240 240 240 240 240 240 240 240 240 240 240 240 240 240 240
			240 240 240 240 240 240 240 240 240 240 240 240 240 240 240 240 240 240
			240 240 240 240 240 240 240 240 240 240 240 240 240 240 240 240 240 240
			240 240 240 240 240 240 240 240 240 240 240 240 240 240 240 240 240 240
			240 240 240 240 240 240 240 240 240 240 240 240 240 240 240 240 240 240
			240 240 240 240 240 240 240 240 240 240 240 240 240 240 240 240 240 240
			240 240 240 240 240 240 240 240 240 240 240 240 240 240 240 240 240 240
			240 240 240 240 240 240 240 240 240 240 240 240 240 240 240 240 240 240
			240 240 240 240 240 240 240 240 240 240 240 240 240 240 240 240 240 240
			240 240 240 240 240 240 240 240 240 240 240 240 240 240 240 240 240 240
			240 240 240 240 240 240 240 240 240 240 240 240 240 240 240 240 240 240
			240 240 240 240 240 240 240 240 240 240 240 240 240 240 240 240 240 240
			240 240 240 240 240 240 240 240 240 240 240 240 240 240 240 240 240 240
			240 240 240 240 240 240 240 240 240 240 240 240 240 240 240 240 240 240
			240 240 240 240 240 240 240 240 240 240 240 240 240 240 240 240 240 240
			240 240 240 240 240 240 240 240 240 240 240 240 240 240 240 240 240 240
			240 240 240 240 240 240 240 240 240 240 240 240 240 240 240 240 240 240
			240 240 240 240 240 240 240 240 240 240 240 240 240 240 240 240 240 240
			240 240 240 240 240 240 240 240 240 240 240 240 240 240 240 240 240 240
			240 240 240 240 240 240 240 240 240 240 240 240 240 240 240 240 240 240
			240 240 240 240 240 240 240 240 240 240 240 240 240 240 240 240 240 240
			240 240 240 240 240 240 240 240 240 240 240 240 240 240 240 240 240 240
			240 240 240 240 240 240 240 240 240 240 240 240 240 240 240 240 240 240
			240 240 240 240 240 240 240 240 240 240 240 240 240 240 240 240 240 240
			240 240 240 240 240 240 240 240 240 240 240 240 240 240 240 240 240 240
			240 240 240 240 240 240 240 240 240 240 240 240 240 240 240 240 240 240
			240 240 240 240 240 240 240 240 240 240 240 240 240 240 240 240 240 240
			240 240 240 240 240 240 240 240 240 240 240 240 240 240 240 240 240 240
			>;

		PS_Config_Lmt_LPWG_Diff_P = <
			90 90 90 90 90 90 90 90 90 90 90 90 90 90 90 90 90 90
			90 90 90 90 90 90 90 90 90 90 90 90 90 90 90 90 90 90
			90 90 90 90 90 90 90 90 90 90 90 90 90 90 90 90 90 90
			90 90 90 90 90 90 90 90 90 90 90 90 90 90 90 90 90 90
			90 90 90 90 90 90 90 90 90 90 90 90 90 90 90 90 90 90
			90 90 90 90 90 90 90 90 90 90 90 90 90 90 90 90 90 90
			90 90 90 90 90 90 90 90 90 90 90 90 90 90 90 90 90 90
			90 90 90 90 90 90 90 90 90 90 90 90 90 90 90 90 90 90
			90 90 90 90 90 90 90 90 90 90 90 90 90 90 90 90 90 90
			90 90 90 90 90 90 90 90 90 90 90 90 90 90 90 90 90 90
			90 90 90 90 90 90 90 90 90 90 90 90 90 90 90 90 90 90
			90 90 90 90 90 90 90 90 90 90 90 90 90 90 90 90 90 90
			90 90 90 90 90 90 90 90 90 90 90 90 90 90 90 90 90 90
			90 90 90 90 90 90 90 90 90 90 90 90 90 90 90 90 90 90
			90 90 90 90 90 90 90 90 90 90 90 90 90 90 90 90 90 90
			90 90 90 90 90 90 90 90 90 90 90 90 90 90 90 90 90 90
			90 90 90 90 90 90 90 90 90 90 90 90 90 90 90 90 90 90
			90 90 90 90 90 90 90 90 90 90 90 90 90 90 90 90 90 90
			90 90 90 90 90 90 90 90 90 90 90 90 90 90 90 90 90 90
			90 90 90 90 90 90 90 90 90 90 90 90 90 90 90 90 90 90
			90 90 90 90 90 90 90 90 90 90 90 90 90 90 90 90 90 90
			90 90 90 90 90 90 90 90 90 90 90 90 90 90 90 90 90 90
			90 90 90 90 90 90 90 90 90 90 90 90 90 90 90 90 90 90
			90 90 90 90 90 90 90 90 90 90 90 90 90 90 90 90 90 90
			90 90 90 90 90 90 90 90 90 90 90 90 90 90 90 90 90 90
			90 90 90 90 90 90 90 90 90 90 90 90 90 90 90 90 90 90
			90 90 90 90 90 90 90 90 90 90 90 90 90 90 90 90 90 90
			90 90 90 90 90 90 90 90 90 90 90 90 90 90 90 90 90 90
			90 90 90 90 90 90 90 90 90 90 90 90 90 90 90 90 90 90
			90 90 90 90 90 90 90 90 90 90 90 90 90 90 90 90 90 90
			90 90 90 90 90 90 90 90 90 90 90 90 90 90 90 90 90 90
			90 90 90 90 90 90 90 90 90 90 90 90 90 90 90 90 90 90
			>;

		PS_Config_Lmt_LPWG_Diff_N = <
			(-90) (-90) (-90) (-90) (-90) (-90) (-90) (-90) (-90) (-90) (-90) (-90) (-90) (-90) (-90) (-90) (-90) (-90)
			(-90) (-90) (-90) (-90) (-90) (-90) (-90) (-90) (-90) (-90) (-90) (-90) (-90) (-90) (-90) (-90) (-90) (-90)
			(-90) (-90) (-90) (-90) (-90) (-90) (-90) (-90) (-90) (-90) (-90) (-90) (-90) (-90) (-90) (-90) (-90) (-90)
			(-90) (-90) (-90) (-90) (-90) (-90) (-90) (-90) (-90) (-90) (-90) (-90) (-90) (-90) (-90) (-90) (-90) (-90)
			(-90) (-90) (-90) (-90) (-90) (-90) (-90) (-90) (-90) (-90) (-90) (-90) (-90) (-90) (-90) (-90) (-90) (-90)
			(-90) (-90) (-90) (-90) (-90) (-90) (-90) (-90) (-90) (-90) (-90) (-90) (-90) (-90) (-90) (-90) (-90) (-90)
			(-90) (-90) (-90) (-90) (-90) (-90) (-90) (-90) (-90) (-90) (-90) (-90) (-90) (-90) (-90) (-90) (-90) (-90)
			(-90) (-90) (-90) (-90) (-90) (-90) (-90) (-90) (-90) (-90) (-90) (-90) (-90) (-90) (-90) (-90) (-90) (-90)
			(-90) (-90) (-90) (-90) (-90) (-90) (-90) (-90) (-90) (-90) (-90) (-90) (-90) (-90) (-90) (-90) (-90) (-90)
			(-90) (-90) (-90) (-90) (-90) (-90) (-90) (-90) (-90) (-90) (-90) (-90) (-90) (-90) (-90) (-90) (-90) (-90)
			(-90) (-90) (-90) (-90) (-90) (-90) (-90) (-90) (-90) (-90) (-90) (-90) (-90) (-90) (-90) (-90) (-90) (-90)
			(-90) (-90) (-90) (-90) (-90) (-90) (-90) (-90) (-90) (-90) (-90) (-90) (-90) (-90) (-90) (-90) (-90) (-90)
			(-90) (-90) (-90) (-90) (-90) (-90) (-90) (-90) (-90) (-90) (-90) (-90) (-90) (-90) (-90) (-90) (-90) (-90)
			(-90) (-90) (-90) (-90) (-90) (-90) (-90) (-90) (-90) (-90) (-90) (-90) (-90) (-90) (-90) (-90) (-90) (-90)
			(-90) (-90) (-90) (-90) (-90) (-90) (-90) (-90) (-90) (-90) (-90) (-90) (-90) (-90) (-90) (-90) (-90) (-90)
			(-90) (-90) (-90) (-90) (-90) (-90) (-90) (-90) (-90) (-90) (-90) (-90) (-90) (-90) (-90) (-90) (-90) (-90)
			(-90) (-90) (-90) (-90) (-90) (-90) (-90) (-90) (-90) (-90) (-90) (-90) (-90) (-90) (-90) (-90) (-90) (-90)
			(-90) (-90) (-90) (-90) (-90) (-90) (-90) (-90) (-90) (-90) (-90) (-90) (-90) (-90) (-90) (-90) (-90) (-90)
			(-90) (-90) (-90) (-90) (-90) (-90) (-90) (-90) (-90) (-90) (-90) (-90) (-90) (-90) (-90) (-90) (-90) (-90)
			(-90) (-90) (-90) (-90) (-90) (-90) (-90) (-90) (-90) (-90) (-90) (-90) (-90) (-90) (-90) (-90) (-90) (-90)
			(-90) (-90) (-90) (-90) (-90) (-90) (-90) (-90) (-90) (-90) (-90) (-90) (-90) (-90) (-90) (-90) (-90) (-90)
			(-90) (-90) (-90) (-90) (-90) (-90) (-90) (-90) (-90) (-90) (-90) (-90) (-90) (-90) (-90) (-90) (-90) (-90)
			(-90) (-90) (-90) (-90) (-90) (-90) (-90) (-90) (-90) (-90) (-90) (-90) (-90) (-90) (-90) (-90) (-90) (-90)
			(-90) (-90) (-90) (-90) (-90) (-90) (-90) (-90) (-90) (-90) (-90) (-90) (-90) (-90) (-90) (-90) (-90) (-90)
			(-90) (-90) (-90) (-90) (-90) (-90) (-90) (-90) (-90) (-90) (-90) (-90) (-90) (-90) (-90) (-90) (-90) (-90)
			(-90) (-90) (-90) (-90) (-90) (-90) (-90) (-90) (-90) (-90) (-90) (-90) (-90) (-90) (-90) (-90) (-90) (-90)
			(-90) (-90) (-90) (-90) (-90) (-90) (-90) (-90) (-90) (-90) (-90) (-90) (-90) (-90) (-90) (-90) (-90) (-90)
			(-90) (-90) (-90) (-90) (-90) (-90) (-90) (-90) (-90) (-90) (-90) (-90) (-90) (-90) (-90) (-90) (-90) (-90)
			(-90) (-90) (-90) (-90) (-90) (-90) (-90) (-90) (-90) (-90) (-90) (-90) (-90) (-90) (-90) (-90) (-90) (-90)
			(-90) (-90) (-90) (-90) (-90) (-90) (-90) (-90) (-90) (-90) (-90) (-90) (-90) (-90) (-90) (-90) (-90) (-90)
			(-90) (-90) (-90) (-90) (-90) (-90) (-90) (-90) (-90) (-90) (-90) (-90) (-90) (-90) (-90) (-90) (-90) (-90)
			(-90) (-90) (-90) (-90) (-90) (-90) (-90) (-90) (-90) (-90) (-90) (-90) (-90) (-90) (-90) (-90) (-90) (-90)
			>;
	}; /* novatek-mp-criteria-hlt */
    };
};
//#endif
/* TOUCH end */

&i2c0 {
      lcm_bias@3e{
               compatible = "LCD_BIAS_SM5109","LCD_BIAS_NT50358A";
               reg = <0x3e>;
               status = "okay";
       };
};
&i2c2 {
	clock-frequency = <400000>;

	mtk-usb@60 {
		compatible = "mediatek,mtk-usb";
		reg = <0x60>;
		status = "okay";
	};
};

/* accdet start */
&accdet {
	/* accdet micbias voltage: 0x07,2.7v;0x05,2.5v;0x02,1.9v */
	accdet-mic-vol = <6>;
	headset-mode-setting = <0x500 0x500 1 0x1f0 0x800 0x800 0x20 0x44>;
	accdet-plugout-debounce = <1>;
	/*1:ACC mode, 2:low cost without in bias, 6:low cost with in bias*/
	accdet-mic-mode = <1>;
	/* eint_level_trigger: 8,LEVEL_LOW(DEF) ;4,LV_HIGH;others,LV_LOW */
	headset-eint-level-pol = <8>;
	/*0--MD_MAX--UP_MAX--DW_MAX*/
	headset-three-key-threshold = <0 80 220 400>;
	headset-three-key-threshold-CDD = <0 121 192 600>;
	/*0--MD_MAX--VOICE_MAX--UP_MAX--DW_MAX*/
	headset-four-key-threshold = <0 58 121 192 400>;
	status = "okay";
};
/* accdet end */

&mt6370_pmu {
	mt6370,intr_gpio_num = <20>; /* direct defined GPIO num */
	mt6370,intr_gpio = <&pio 20 0x0>;
};
&mt6370_typec {
	mt6370pd,intr_gpio_num = <41>; /* direct defined GPIO num */
	mt6370pd,intr_gpio = <&pio 41 0x0>;
};

/* CONSYS GPIO standardization */
&pio {
	consys_pins_default: consys_default {
	};
	gpslna_pins_init: gpslna@0 {
	};
	gpslna_pins_oh: gpslna@1 {
	};
	gpslna_pins_ol: gpslna@2 {
	};
};
&consys {
	pinctrl-names = "default", "gps_lna_state_init",
		"gps_lna_state_oh", "gps_lna_state_ol";
	pinctrl-0 = <&consys_pins_default>;
	pinctrl-1 = <&gpslna_pins_init>;
	pinctrl-2 = <&gpslna_pins_oh>;
	pinctrl-3 = <&gpslna_pins_ol>;
	status = "okay";
};
/* CONSYS end */

/* IRTX GPIO Start */
&irtx_pwm {
	pinctrl-names = "irtx_gpio_led_default", "irtx_gpio_led_set";
	pinctrl-0 = <&irtx_gpio_led_default>;
	pinctrl-1 = <&irtx_gpio_led_set>;
	status = "okay";
};
&pio {
	/* IRTX GPIO Settings -Start */
	/* default: GPIO0, output, high */
	irtx_gpio_led_default:irtx_gpio_led_def@gpio12 {
		pins_cmd_dat {
			pinmux = <PINMUX_GPIO12__FUNC_GPIO12>;
			slew-rate = <1>;
			bias-disable;
			output-low;
			input-schmitt-enable = <0>;
		};
	};

	irtx_gpio_led_set:irtx_gpio_led_set@gpio12 {
		pins_cmd_dat {
			pinmux = <PINMUX_GPIO12__FUNC_PWM0>;
			slew-rate = <1>;
			output-high;
		};
	};
}; /* IRTX GPIO Settings -End */

/* DISPSYS GPIO standardization */
&pio {
	mtkfb_pins_lcm_rst_out1_gpio: lcm_rst_out1_gpio {
		pins_cmd_dat {
			pinmux = <PINMUX_GPIO45__FUNC_GPIO45>;
			slew-rate = <1>;
			output-high;
		};
	};

	mtkfb_pins_lcm_rst_out0_gpio: lcm_rst_out0_gpio {
		pins_cmd_dat {
			pinmux = <PINMUX_GPIO45__FUNC_GPIO45>;
			slew-rate = <1>;
			output-low;
		};
	};

	mtkfb_pins_lcm_dsi_te: lcm_dsi_te {
		pins_cmd_dat {
			pinmux = <PINMUX_GPIO44__FUNC_DSI_TE>;
		};
	};
};

/*&mtkfb {
	pinctrl-names =
		"lcm_rst_out1_gpio", "lcm_rst_out0_gpio",
		"mode_te_te";
	pinctrl-0 = <&mtkfb_pins_lcm_rst_out1_gpio>;
	pinctrl-1 = <&mtkfb_pins_lcm_rst_out0_gpio>;
	pinctrl-2 = <&mtkfb_pins_lcm_dsi_te>;
	status = "okay";
};*/
/* Hao.Liang@ODM_WT.MM.Display.Lcd, 2019/9/25, LCD bringup */
/* DISPSYS GPIO standardization */
&mtkfb {
        pinctrl-names = "lcm_rst_out0_gpio", "lcm_rst_out1_gpio", "lcd_bias_enp0_gpio", "lcd_bias_enp1_gpio",
			"lcd_bias_enn0_gpio", "lcd_bias_enn1_gpio", "lcd_vddio18_en0_gpio", "lcd_vddio18_en1_gpio";

	pinctrl-0 = <&mtkfb_pins_lcm_reset0>;
	pinctrl-1 = <&mtkfb_pins_lcm_reset1>;
	pinctrl-2 = <&mtkfb_pins_lcd_bias_enp0>;
	pinctrl-3 = <&mtkfb_pins_lcd_bias_enp1>;
	pinctrl-4 = <&mtkfb_pins_lcd_bias_enn0>;
	pinctrl-5 = <&mtkfb_pins_lcd_bias_enn1>;
	//pinctrl-6 = <&mtkfb_pins_lcd_vddio18_en0>;
	//pinctrl-7 = <&mtkfb_pins_lcd_vddio18_en1>;
        status = "okay";
};

&pio {
        mtkfb_pins_lcm_reset0: lcm_rst_out0_gpio {
                pins_cmd_dat {
                        pinmux = <PINMUX_GPIO45__FUNC_GPIO45>;
                        slew-rate = <1>;
                        output-low;
                };
        };
        mtkfb_pins_lcm_reset1: lcm_rst_out1_gpio {
                pins_cmd_dat {
                        pinmux = <PINMUX_GPIO45__FUNC_GPIO45>;
                        slew-rate = <1>;
                        output-high;
                };
        };

	mtkfb_pins_lcd_bias_enp0: lcd_bias_enp0_gpio {
                pins_cmd_dat {
                        pinmux = <PINMUX_GPIO169__FUNC_GPIO169>;
                        slew-rate = <1>;
                        output-low;
                };
        };
	mtkfb_pins_lcd_bias_enp1: lcd_bias_enp1_gpio {
                pins_cmd_dat {
                        pinmux = <PINMUX_GPIO169__FUNC_GPIO169>;
                        slew-rate = <1>;
                        output-high;
                };
        };

	mtkfb_pins_lcd_bias_enn0: lcd_bias_enn0_gpio {
                pins_cmd_dat {
                        pinmux = <PINMUX_GPIO165__FUNC_GPIO165>;
                        slew-rate = <1>;
                        output-low;
                };
        };
	mtkfb_pins_lcd_bias_enn1: lcd_bias_enn1_gpio {
                pins_cmd_dat {
                        pinmux = <PINMUX_GPIO165__FUNC_GPIO165>;
                        slew-rate = <1>;
                        output-high;
                };
        };

/*	mtkfb_pins_lcd_vddio18_en0: lcd_vddio18_en0_gpio {
                pins_cmd_dat {
                        pinmux = <PINMUX_GPIO170__FUNC_GPIO170>;
                        slew-rate = <1>;
                        output-low;
                };
        };
	mtkfb_pins_lcd_vddio18_en1: lcd_vddio18_en1_gpio {
                pins_cmd_dat {
                        pinmux = <PINMUX_GPIO170__FUNC_GPIO170>;
                        slew-rate = <1>;
                        output-high;
                };
        };*/
};
/* Hao.Liang@ODM_WT.MM.Display.Lcd, 2019/9/25, LCD bringup */
/* DISPSYS GPIO standardization end*/

/*Shouli.Wang@ODM_WT.BSP.CHG 2019/9/25, charger bringup start*/
&bat_gm30 {
		io-channels = <&auxadc 2>;
		io-channel-names = "batteryID-channel";	
};
//#include "rt9471_single.dtsi"
/*Shouli.Wang@ODM_WT.BSP.CHG 2019/9/25, charger bringup end*/
//#ifdef ODM_WT_EDIT
/*Shouli.Wang@ODM_WT.BSP.CHG 2019/10/07, modify monet charger params*/
&charger {
	ac_charger_input_current = <2000000>;
	ac_charger_current = <2000000>;
	/delete-node/ enable_type_c;
};
//#endif /*ODM_WT_EDIT*/

//#ifdef ODM_WT_EDIT
//Mingyao.Xie@ODM_WT.BSP.Storage.Usb, 2018/08/07, Modify for OTG
&otg_iddig	{
		compatible = "mediatek,usb_iddig_bi_eint";
		interrupt-parent = <&pio>;
		interrupts = <147 IRQ_TYPE_LEVEL_LOW 147 0>;
		status = "okay";
	};
//#endif

#include <oppo6769_19747/cust.dtsi>
#include "cust_mt6768_camera.dtsi"
/*End of this file, DO NOT ADD ANYTHING HERE*/
